AUTOSAR XML (schema 4-2-2)
package /Components
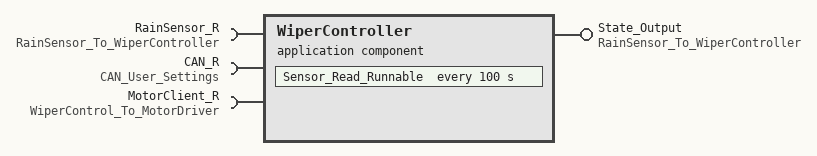
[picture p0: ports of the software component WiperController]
  application sw component type WiperController
    provide port State_Output: provided-interface=RainSensor_To_WiperController
    provide/require port Motor_PR: provided-required-interface=WiperControl_To_MotorDriver
    require port RainSensor_R: required-interface=RainSensor_To_WiperController
    require port CAN_R: required-interface=CAN_User_Settings
    require port MotorClient_R: required-interface=WiperControl_To_MotorDriver
    behavior WiperController_Behavior
      data received event RainDataReceived: start-on-event=Sensor_Read_Runnable
      external trigger occurred event CANSettingsReceived: start-on-event=Sensor_Read_Runnable
      timing event ControlCycleEvent: start-on-event=Sensor_Read_Runnable, period=100
      4 x runnable:
        Can_Rx_Runnable: minimum-start-interval=50, symbol=WIPER_CAN_RX
          data-receive-point-by-arguments:
            access CanInputVar: accessed-variable={autosar-variable=CAN_R.CanUserSettings, local-variable=CanSettings}
          data-receive-point-by-values:
            access CanInputVal: accessed-variable={autosar-variable=CAN_R.CanUserSettings, local-variable=CanSettings}
          mode switch point ModeSwitchPoint_CAN: mode-group=State_Output.WiperModeGroup
        Sensor_Process_Runnable: minimum-start-interval=50, symbol=WIPER_SENSOR_PROC
          data-receive-point-by-arguments:
            access RainArg: accessed-variable={autosar-variable=RainSensor_R.rain_level, local-variable=BufferedRainLevel}
          data-receive-point-by-values:
            access RainVal: accessed-variable={autosar-variable=RainSensor_R.rain_level, local-variable=BufferedRainLevel}
          mode switch point ModeSwitchPoint_Sensor: mode-group=State_Output.WiperModeGroup
        Mode_Manager_Runnable: minimum-start-interval=100, symbol=WIPER_MODE_MGR
          data-receive-point-by-arguments:
            access ModeInput: accessed-variable={autosar-variable=CAN_R.CanUserSettings, local-variable=CurrentMode}
          data-receive-point-by-values:
            access ModeVal: accessed-variable={autosar-variable=CAN_R.CanUserSettings, local-variable=CurrentMode}
          mode switch point ModeSwitchPoint_Manager: mode-group=State_Output.WiperModeGroup
        Control_Logic_Runnable: minimum-start-interval=100, symbol=WIPER_CTRL_LOGIC
          data-receive-point-by-arguments:
            access ControlArgs: accessed-variable={autosar-variable=RainSensor_R.rain_level, local-variable=FilteredRainLevel}
          data-receive-point-by-values:
            access ControlVals: accessed-variable={autosar-variable=CAN_R.CanUserSettings, local-variable=TargetSpeed}
          mode switch point ModeSwitchPoint_Control: mode-group=State_Output.WiperModeGroup
          sync call CallMotorDriver: called-from-within-exclusive-area=WiperControllerEA, operation=MotorClient_R.ControlCommand, timeout=20
